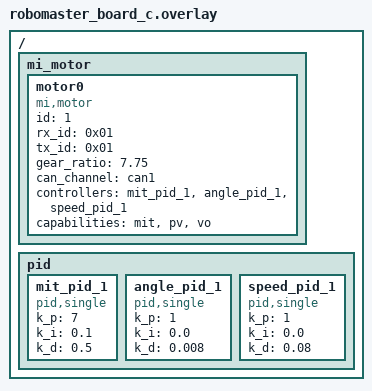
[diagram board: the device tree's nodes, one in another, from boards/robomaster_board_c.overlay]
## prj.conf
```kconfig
#启用线程分析器
# CONFIG_THREAD_ANALYZER=y
# CONFIG_THREAD_ANALYZER_USE_LOG=y
# CONFIG_THREAD_ANALYZER_USE_PRINTK=n
# CONFIG_THREAD_NAME=y
# CONFIG_THREAD_ANALYZER_AUTO=y
# CONFIG_THREAD_ANALYZER_AUTO_INTERVAL=5
# CONFIG_THREAD_ANALYZER_LOG_LEVEL_INF=y
# CONFIG_THREAD_ANALYZER_AUTO_SEPARATE_CORES=n

# 启用 Shell 支持
CONFIG_SHELL=n
CONFIG_SHELL_BACKENDS=n
CONFIG_SHELL_BACKEND_SERIAL=n

# 启用 UART 控制台
CONFIG_UART_CONSOLE=y

# 禁用 SEGGER RTT
CONFIG_USE_SEGGER_RTT=n

# 启用事件支持
CONFIG_EVENTS=y

# 启用控制台支持
CONFIG_CONSOLE=y

# 启用日志系统
CONFIG_LOG=y
CONFIG_LOG_MODE_IMMEDIATE=y
CONFIG_LOG_PRINTK=y
CONFIG_LOG_BACKEND_UART=y
CONFIG_LOG_MODE_IMMEDIATE=y

# 启用串行支持
CONFIG_SERIAL=y
CONFIG_SPI_ASYNC=y
# 禁用优化
CONFIG_NO_OPTIMIZATIONS=y

# 启用驱动
CONFIG_MOTOR=y
# CONFIG_MOTOR_DJI=y
CONFIG_MOTOR_MI=y
CONFIG_MOTOR_LOG_LEVEL=4
CONFIG_CAN=y
CONFIG_MOTOR_INIT_PRIORITY=90
CONFIG_PID=y

CONFIG_ARES=y
CONFIG_ARES_SBUS=y
CONFIG_SBUS_INIT_PRIORITY=90

# use ASYNC uart API
CONFIG_SERIAL=y
CONFIG_UART_ASYNC_API=y
CONFIG_UART_INTERRUPT_DRIVEN=y

CONFIG_DMA=y
CONFIG_DMA_STM32=y  # STM32 DMA 驱动
CONFIG_UART_STM32=y # STM32 UART 驱动
# CONFIG_STM32_UART_DMA=y

# CONFIG_HAS_STM32CUBE=y
# CONFIG_USE_STM32_HAL_DMA=y
# CONFIG_SPI=y
# CONFIG_SPI_STM32=y

#
# Device Drivers
#
# CONFIG_SENSOR=y
# CONFIG_BMI08X=y
# CONFIG_BMI08X_ACCEL_TRIGGER_NONE is not set
# CONFIG_BMI08X_ACCEL_TRIGGER_GLOBAL_THREAD=y
# CONFIG_BMI08X_ACCEL_TRIGGER_OWN_THREAD is not set
# CONFIG_BMI08X_GYRO_TRIGGER_NONE is not set
# CONFIG_BMI08X_GYRO_TRIGGER_GLOBAL_THREAD=y
# CONFIG_BMI08X_GYRO_TRIGGER_OWN_THREAD is not set
# CONFIG_BMI08X_I2C_WRITE_BURST_SIZE=16

CONFIG_DEBUG_THREAD_INFO=y
```

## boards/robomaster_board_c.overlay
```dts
/ {
	mi_motor {
		motor0: motor0{
			compatible = "mi,motor";
            
			id = <1>;
            rx_id = <0x01>;
            tx_id = <0x01>;
			gear_ratio = "7.75";
			status = "okay";
			can_channel = <&can1>;
			controllers = <&mit_pid_1 &angle_pid_1 &speed_pid_1>;
			capabilities = "mit","pv", "vo";
		};

		
	};

	pid {
		mit_pid_1: mit_pid_1 {
			#controller-cells = <0>;
			compatible = "pid,single";
			k_p = "7";
			k_i = "0.1";
			k_d = "0.5";
		};
		angle_pid_1: angle_pid_1 {
			#controller-cells = <0>;
			compatible = "pid,single";
			k_p = "1";
			k_i = "0.0";
			k_d = "0.008";
		};
		speed_pid_1: speed_pid_1 {
			#controller-cells = <0>;
			compatible = "pid,single";
			k_p = "1";
			k_i = "0.0";
			k_d = "0.08";
		};
		
	};
	
};
```

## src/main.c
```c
#include "ares/board/init.h"
#include <math.h>
#include <stddef.h>
#include <stdint.h>
#include <stdio.h>
#include <zephyr/debug/thread_analyzer.h>
#include <zephyr/device.h>
#include <zephyr/devicetree.h>
#include <zephyr/drivers/can.h>
#include <zephyr/drivers/motor.h>
#include <zephyr/drivers/sbus.h>
#include <zephyr/drivers/sensor.h>
#include <zephyr/drivers/uart.h>
#include <zephyr/kernel.h>
#include <zephyr/logging/log.h>
#include <zephyr/sys/printk.h>

LOG_MODULE_REGISTER(main, LOG_LEVEL_DBG);

#define G 9.80665f

#define HIGH_BYTE(x) ((x) >> 8)
#define LOW_BYTE(x) ((x)&0xFF)
#define COMBINE_HL8(HIGH, LOW) ((HIGH << 8) + LOW)

#define MOTOR1_NODE DT_INST(0, mi_motor)

const struct device *motor1 = DEVICE_DT_GET(MOTOR1_NODE);

#define CPU_NODE DT_NODELABEL(cpu0)

const struct device *cpu_dev = DEVICE_DT_GET(CPU_NODE);

k_tid_t feedback_tid = 0;

float motor1_rpm = 0;
float motor2_rpm = 0;

/* CAN Feedback to console*/
K_THREAD_STACK_DEFINE(feedback_stack_area, 4096); // 定义线程栈
void console_feedback(void *arg1, void *arg2, void *arg3) {

  while (1) {
    LOG_INF(" motor1: %.2f %.2f\n", (double)motor1_rpm,
            (double)motor_get_angle(motor1));

    k_msleep(200);
  }
}

int main(void) {
  // board_init();
  LOG_INF("yes");
  k_sleep(K_MSEC(1000));
  // motor_control(motor1, ENABLE_MOTOR);

  motor_set_mode(motor1, MIT);
  /* Start Feedback thread*/
  struct k_thread feedback_thread_data;
  feedback_tid = k_thread_create(
      &feedback_thread_data,
      feedback_stack_area, // 修改为 can_send_stack_area
      K_THREAD_STACK_SIZEOF(feedback_stack_area), console_feedback,
      (void *)motor1, NULL, NULL, 0, 0, K_MSEC(300));
  motor_control(motor1, SET_ZERO);
  while (1) {

    motor_set_speed(motor1, 10);
    motor_set_torque(motor1, 0.1);
    motor_set_angle(motor1, 360);

    k_msleep(500);
  }
}
```
